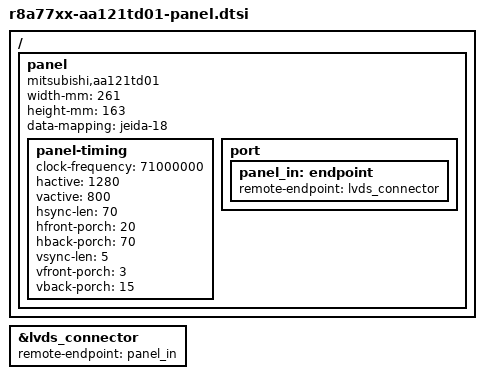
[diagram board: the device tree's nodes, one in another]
/ {
	panel {
		compatible = "mitsubishi,aa121td01", "panel-lvds";
		width-mm = <261>;
		height-mm = <163>;
		data-mapping = "jeida-18";
		panel-timing {
			clock-frequency = <71000000>;
			hactive = <1280>;
			vactive = <800>;
			hsync-len = <70>;
			hfront-porch = <20>;
			hback-porch = <70>;
			vsync-len = <5>;
			vfront-porch = <3>;
			vback-porch = <15>;
		};
		port {
			panel_in: endpoint {
				remote-endpoint = <&lvds_connector>;
			};
		};
	};
};
&lvds_connector {
	remote-endpoint = <&panel_in>;
};
